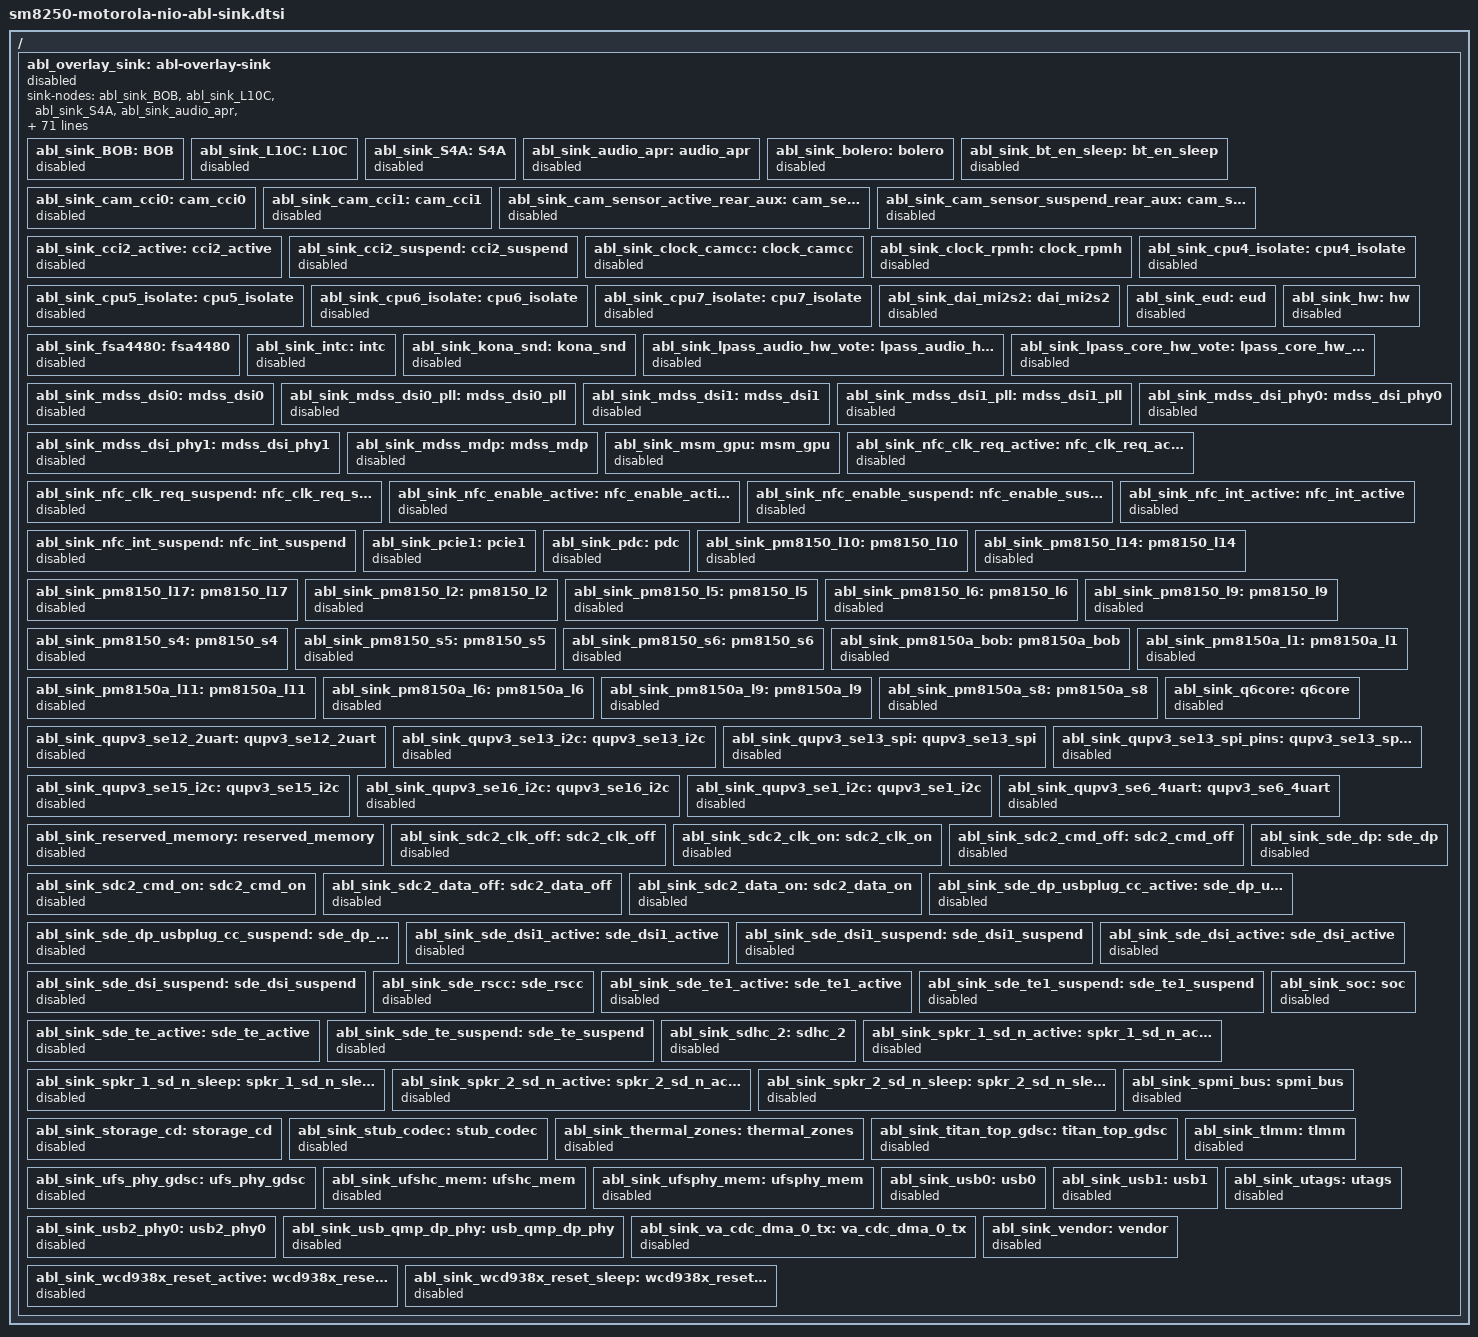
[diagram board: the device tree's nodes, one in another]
// SPDX-License-Identifier: BSD-3-Clause
/* Generated by tools/gen_abl_overlay_sink.py from dtbo sha256 52f8313a3153f082198788da3f1743398a164f1865f6db5d3dace15b3edebf47.
 * Fastboot-boot only: absorbs the stock ABL dtbo overlay. Do not edit. */

/ {
	abl_overlay_sink: abl-overlay-sink {
		status = "disabled";
		/* References make dtc emit a phandle for every sink node. */
		sink-nodes = <&abl_sink_BOB &abl_sink_L10C &abl_sink_S4A &abl_sink_audio_apr &abl_sink_bolero &abl_sink_bt_en_sleep &abl_sink_cam_cci0 &abl_sink_cam_cci1 &abl_sink_cam_sensor_active_rear_aux &abl_sink_cam_sensor_suspend_rear_aux &abl_sink_cci2_active &abl_sink_cci2_suspend &abl_sink_clock_camcc &abl_sink_clock_rpmh &abl_sink_cpu4_isolate &abl_sink_cpu5_isolate &abl_sink_cpu6_isolate &abl_sink_cpu7_isolate &abl_sink_dai_mi2s2 &abl_sink_eud &abl_sink_fsa4480 &abl_sink_hw &abl_sink_intc &abl_sink_kona_snd &abl_sink_lpass_audio_hw_vote &abl_sink_lpass_core_hw_vote &abl_sink_mdss_dsi0 &abl_sink_mdss_dsi0_pll &abl_sink_mdss_dsi1 &abl_sink_mdss_dsi1_pll &abl_sink_mdss_dsi_phy0 &abl_sink_mdss_dsi_phy1 &abl_sink_mdss_mdp &abl_sink_msm_gpu &abl_sink_nfc_clk_req_active &abl_sink_nfc_clk_req_suspend &abl_sink_nfc_enable_active &abl_sink_nfc_enable_suspend &abl_sink_nfc_int_active &abl_sink_nfc_int_suspend &abl_sink_pcie1 &abl_sink_pdc &abl_sink_pm8150_l10 &abl_sink_pm8150_l14 &abl_sink_pm8150_l17 &abl_sink_pm8150_l2 &abl_sink_pm8150_l5 &abl_sink_pm8150_l6 &abl_sink_pm8150_l9 &abl_sink_pm8150_s4 &abl_sink_pm8150_s5 &abl_sink_pm8150_s6 &abl_sink_pm8150a_bob &abl_sink_pm8150a_l1 &abl_sink_pm8150a_l11 &abl_sink_pm8150a_l6 &abl_sink_pm8150a_l9 &abl_sink_pm8150a_s8 &abl_sink_q6core &abl_sink_qupv3_se12_2uart &abl_sink_qupv3_se13_i2c &abl_sink_qupv3_se13_spi &abl_sink_qupv3_se13_spi_pins &abl_sink_qupv3_se15_i2c &abl_sink_qupv3_se16_i2c &abl_sink_qupv3_se1_i2c &abl_sink_qupv3_se6_4uart &abl_sink_reserved_memory &abl_sink_sdc2_clk_off &abl_sink_sdc2_clk_on &abl_sink_sdc2_cmd_off &abl_sink_sdc2_cmd_on &abl_sink_sdc2_data_off &abl_sink_sdc2_data_on &abl_sink_sde_dp &abl_sink_sde_dp_usbplug_cc_active &abl_sink_sde_dp_usbplug_cc_suspend &abl_sink_sde_dsi1_active &abl_sink_sde_dsi1_suspend &abl_sink_sde_dsi_active &abl_sink_sde_dsi_suspend &abl_sink_sde_rscc &abl_sink_sde_te1_active &abl_sink_sde_te1_suspend &abl_sink_sde_te_active &abl_sink_sde_te_suspend &abl_sink_sdhc_2 &abl_sink_soc &abl_sink_spkr_1_sd_n_active &abl_sink_spkr_1_sd_n_sleep &abl_sink_spkr_2_sd_n_active &abl_sink_spkr_2_sd_n_sleep &abl_sink_spmi_bus &abl_sink_storage_cd &abl_sink_stub_codec &abl_sink_thermal_zones &abl_sink_titan_top_gdsc &abl_sink_tlmm &abl_sink_ufs_phy_gdsc &abl_sink_ufshc_mem &abl_sink_ufsphy_mem &abl_sink_usb0 &abl_sink_usb1 &abl_sink_usb2_phy0 &abl_sink_usb_qmp_dp_phy &abl_sink_utags &abl_sink_va_cdc_dma_0_tx &abl_sink_vendor &abl_sink_wcd938x_reset_active &abl_sink_wcd938x_reset_sleep>;

		abl_sink_BOB: BOB {
			status = "disabled";
		};
		abl_sink_L10C: L10C {
			status = "disabled";
		};
		abl_sink_S4A: S4A {
			status = "disabled";
		};
		abl_sink_audio_apr: audio_apr {
			status = "disabled";
		};
		abl_sink_bolero: bolero {
			status = "disabled";
		};
		abl_sink_bt_en_sleep: bt_en_sleep {
			status = "disabled";
		};
		abl_sink_cam_cci0: cam_cci0 {
			status = "disabled";
		};
		abl_sink_cam_cci1: cam_cci1 {
			status = "disabled";
		};
		abl_sink_cam_sensor_active_rear_aux: cam_sensor_active_rear_aux {
			status = "disabled";
		};
		abl_sink_cam_sensor_suspend_rear_aux: cam_sensor_suspend_rear_aux {
			status = "disabled";
		};
		abl_sink_cci2_active: cci2_active {
			status = "disabled";
		};
		abl_sink_cci2_suspend: cci2_suspend {
			status = "disabled";
		};
		abl_sink_clock_camcc: clock_camcc {
			status = "disabled";
		};
		abl_sink_clock_rpmh: clock_rpmh {
			status = "disabled";
		};
		abl_sink_cpu4_isolate: cpu4_isolate {
			status = "disabled";
		};
		abl_sink_cpu5_isolate: cpu5_isolate {
			status = "disabled";
		};
		abl_sink_cpu6_isolate: cpu6_isolate {
			status = "disabled";
		};
		abl_sink_cpu7_isolate: cpu7_isolate {
			status = "disabled";
		};
		abl_sink_dai_mi2s2: dai_mi2s2 {
			status = "disabled";
		};
		abl_sink_eud: eud {
			status = "disabled";
		};
		abl_sink_fsa4480: fsa4480 {
			status = "disabled";
		};
		abl_sink_hw: hw {
			status = "disabled";
		};
		abl_sink_intc: intc {
			status = "disabled";
		};
		abl_sink_kona_snd: kona_snd {
			status = "disabled";
		};
		abl_sink_lpass_audio_hw_vote: lpass_audio_hw_vote {
			status = "disabled";
		};
		abl_sink_lpass_core_hw_vote: lpass_core_hw_vote {
			status = "disabled";
		};
		abl_sink_mdss_dsi0: mdss_dsi0 {
			status = "disabled";
		};
		abl_sink_mdss_dsi0_pll: mdss_dsi0_pll {
			status = "disabled";
		};
		abl_sink_mdss_dsi1: mdss_dsi1 {
			status = "disabled";
		};
		abl_sink_mdss_dsi1_pll: mdss_dsi1_pll {
			status = "disabled";
		};
		abl_sink_mdss_dsi_phy0: mdss_dsi_phy0 {
			status = "disabled";
		};
		abl_sink_mdss_dsi_phy1: mdss_dsi_phy1 {
			status = "disabled";
		};
		abl_sink_mdss_mdp: mdss_mdp {
			status = "disabled";
		};
		abl_sink_msm_gpu: msm_gpu {
			status = "disabled";
		};
		abl_sink_nfc_clk_req_active: nfc_clk_req_active {
			status = "disabled";
		};
		abl_sink_nfc_clk_req_suspend: nfc_clk_req_suspend {
			status = "disabled";
		};
		abl_sink_nfc_enable_active: nfc_enable_active {
			status = "disabled";
		};
		abl_sink_nfc_enable_suspend: nfc_enable_suspend {
			status = "disabled";
		};
		abl_sink_nfc_int_active: nfc_int_active {
			status = "disabled";
		};
		abl_sink_nfc_int_suspend: nfc_int_suspend {
			status = "disabled";
		};
		abl_sink_pcie1: pcie1 {
			status = "disabled";
		};
		abl_sink_pdc: pdc {
			status = "disabled";
		};
		abl_sink_pm8150_l10: pm8150_l10 {
			status = "disabled";
		};
		abl_sink_pm8150_l14: pm8150_l14 {
			status = "disabled";
		};
		abl_sink_pm8150_l17: pm8150_l17 {
			status = "disabled";
		};
		abl_sink_pm8150_l2: pm8150_l2 {
			status = "disabled";
		};
		abl_sink_pm8150_l5: pm8150_l5 {
			status = "disabled";
		};
		abl_sink_pm8150_l6: pm8150_l6 {
			status = "disabled";
		};
		abl_sink_pm8150_l9: pm8150_l9 {
			status = "disabled";
		};
		abl_sink_pm8150_s4: pm8150_s4 {
			status = "disabled";
		};
		abl_sink_pm8150_s5: pm8150_s5 {
			status = "disabled";
		};
		abl_sink_pm8150_s6: pm8150_s6 {
			status = "disabled";
		};
		abl_sink_pm8150a_bob: pm8150a_bob {
			status = "disabled";
		};
		abl_sink_pm8150a_l1: pm8150a_l1 {
			status = "disabled";
		};
		abl_sink_pm8150a_l11: pm8150a_l11 {
			status = "disabled";
		};
		abl_sink_pm8150a_l6: pm8150a_l6 {
			status = "disabled";
		};
		abl_sink_pm8150a_l9: pm8150a_l9 {
			status = "disabled";
		};
		abl_sink_pm8150a_s8: pm8150a_s8 {
			status = "disabled";
		};
		abl_sink_q6core: q6core {
			status = "disabled";
		};
		abl_sink_qupv3_se12_2uart: qupv3_se12_2uart {
			status = "disabled";
		};
		abl_sink_qupv3_se13_i2c: qupv3_se13_i2c {
			status = "disabled";
		};
		abl_sink_qupv3_se13_spi: qupv3_se13_spi {
			status = "disabled";
		};
		abl_sink_qupv3_se13_spi_pins: qupv3_se13_spi_pins {
			status = "disabled";
		};
		abl_sink_qupv3_se15_i2c: qupv3_se15_i2c {
			status = "disabled";
		};
		abl_sink_qupv3_se16_i2c: qupv3_se16_i2c {
			status = "disabled";
		};
		abl_sink_qupv3_se1_i2c: qupv3_se1_i2c {
			status = "disabled";
		};
		abl_sink_qupv3_se6_4uart: qupv3_se6_4uart {
			status = "disabled";
		};
		abl_sink_reserved_memory: reserved_memory {
			status = "disabled";
		};
		abl_sink_sdc2_clk_off: sdc2_clk_off {
			status = "disabled";
		};
		abl_sink_sdc2_clk_on: sdc2_clk_on {
			status = "disabled";
		};
		abl_sink_sdc2_cmd_off: sdc2_cmd_off {
			status = "disabled";
		};
		abl_sink_sdc2_cmd_on: sdc2_cmd_on {
			status = "disabled";
		};
		abl_sink_sdc2_data_off: sdc2_data_off {
			status = "disabled";
		};
		abl_sink_sdc2_data_on: sdc2_data_on {
			status = "disabled";
		};
		abl_sink_sde_dp: sde_dp {
			status = "disabled";
		};
		abl_sink_sde_dp_usbplug_cc_active: sde_dp_usbplug_cc_active {
			status = "disabled";
		};
		abl_sink_sde_dp_usbplug_cc_suspend: sde_dp_usbplug_cc_suspend {
			status = "disabled";
		};
		abl_sink_sde_dsi1_active: sde_dsi1_active {
			status = "disabled";
		};
		abl_sink_sde_dsi1_suspend: sde_dsi1_suspend {
			status = "disabled";
		};
		abl_sink_sde_dsi_active: sde_dsi_active {
			status = "disabled";
		};
		abl_sink_sde_dsi_suspend: sde_dsi_suspend {
			status = "disabled";
		};
		abl_sink_sde_rscc: sde_rscc {
			status = "disabled";
		};
		abl_sink_sde_te1_active: sde_te1_active {
			status = "disabled";
		};
		abl_sink_sde_te1_suspend: sde_te1_suspend {
			status = "disabled";
		};
		abl_sink_sde_te_active: sde_te_active {
			status = "disabled";
		};
		abl_sink_sde_te_suspend: sde_te_suspend {
			status = "disabled";
		};
		abl_sink_sdhc_2: sdhc_2 {
			status = "disabled";
		};
		abl_sink_soc: soc {
			status = "disabled";
		};
		abl_sink_spkr_1_sd_n_active: spkr_1_sd_n_active {
			status = "disabled";
		};
		abl_sink_spkr_1_sd_n_sleep: spkr_1_sd_n_sleep {
			status = "disabled";
		};
		abl_sink_spkr_2_sd_n_active: spkr_2_sd_n_active {
			status = "disabled";
		};
		abl_sink_spkr_2_sd_n_sleep: spkr_2_sd_n_sleep {
			status = "disabled";
		};
		abl_sink_spmi_bus: spmi_bus {
			status = "disabled";
		};
		abl_sink_storage_cd: storage_cd {
			status = "disabled";
		};
		abl_sink_stub_codec: stub_codec {
			status = "disabled";
		};
		abl_sink_thermal_zones: thermal_zones {
			status = "disabled";
		};
		abl_sink_titan_top_gdsc: titan_top_gdsc {
			status = "disabled";
		};
		abl_sink_tlmm: tlmm {
			status = "disabled";
		};
		abl_sink_ufs_phy_gdsc: ufs_phy_gdsc {
			status = "disabled";
		};
		abl_sink_ufshc_mem: ufshc_mem {
			status = "disabled";
		};
		abl_sink_ufsphy_mem: ufsphy_mem {
			status = "disabled";
		};
		abl_sink_usb0: usb0 {
			status = "disabled";
		};
		abl_sink_usb1: usb1 {
			status = "disabled";
		};
		abl_sink_usb2_phy0: usb2_phy0 {
			status = "disabled";
		};
		abl_sink_usb_qmp_dp_phy: usb_qmp_dp_phy {
			status = "disabled";
		};
		abl_sink_utags: utags {
			status = "disabled";
		};
		abl_sink_va_cdc_dma_0_tx: va_cdc_dma_0_tx {
			status = "disabled";
		};
		abl_sink_vendor: vendor {
			status = "disabled";
		};
		abl_sink_wcd938x_reset_active: wcd938x_reset_active {
			status = "disabled";
		};
		abl_sink_wcd938x_reset_sleep: wcd938x_reset_sleep {
			status = "disabled";
		};
	};

	__symbols__ {
		BOB = "/abl-overlay-sink/BOB";
		L10C = "/abl-overlay-sink/L10C";
		S4A = "/abl-overlay-sink/S4A";
		audio_apr = "/abl-overlay-sink/audio_apr";
		bolero = "/abl-overlay-sink/bolero";
		bt_en_sleep = "/abl-overlay-sink/bt_en_sleep";
		cam_cci0 = "/abl-overlay-sink/cam_cci0";
		cam_cci1 = "/abl-overlay-sink/cam_cci1";
		cam_sensor_active_rear_aux = "/abl-overlay-sink/cam_sensor_active_rear_aux";
		cam_sensor_suspend_rear_aux = "/abl-overlay-sink/cam_sensor_suspend_rear_aux";
		cci2_active = "/abl-overlay-sink/cci2_active";
		cci2_suspend = "/abl-overlay-sink/cci2_suspend";
		clock_camcc = "/abl-overlay-sink/clock_camcc";
		clock_rpmh = "/abl-overlay-sink/clock_rpmh";
		cpu4_isolate = "/abl-overlay-sink/cpu4_isolate";
		cpu5_isolate = "/abl-overlay-sink/cpu5_isolate";
		cpu6_isolate = "/abl-overlay-sink/cpu6_isolate";
		cpu7_isolate = "/abl-overlay-sink/cpu7_isolate";
		dai_mi2s2 = "/abl-overlay-sink/dai_mi2s2";
		eud = "/abl-overlay-sink/eud";
		fsa4480 = "/abl-overlay-sink/fsa4480";
		hw = "/abl-overlay-sink/hw";
		intc = "/abl-overlay-sink/intc";
		kona_snd = "/abl-overlay-sink/kona_snd";
		lpass_audio_hw_vote = "/abl-overlay-sink/lpass_audio_hw_vote";
		lpass_core_hw_vote = "/abl-overlay-sink/lpass_core_hw_vote";
		mdss_dsi0 = "/abl-overlay-sink/mdss_dsi0";
		mdss_dsi0_pll = "/abl-overlay-sink/mdss_dsi0_pll";
		mdss_dsi1 = "/abl-overlay-sink/mdss_dsi1";
		mdss_dsi1_pll = "/abl-overlay-sink/mdss_dsi1_pll";
		mdss_dsi_phy0 = "/abl-overlay-sink/mdss_dsi_phy0";
		mdss_dsi_phy1 = "/abl-overlay-sink/mdss_dsi_phy1";
		mdss_mdp = "/abl-overlay-sink/mdss_mdp";
		msm_gpu = "/abl-overlay-sink/msm_gpu";
		nfc_clk_req_active = "/abl-overlay-sink/nfc_clk_req_active";
		nfc_clk_req_suspend = "/abl-overlay-sink/nfc_clk_req_suspend";
		nfc_enable_active = "/abl-overlay-sink/nfc_enable_active";
		nfc_enable_suspend = "/abl-overlay-sink/nfc_enable_suspend";
		nfc_int_active = "/abl-overlay-sink/nfc_int_active";
		nfc_int_suspend = "/abl-overlay-sink/nfc_int_suspend";
		pcie1 = "/abl-overlay-sink/pcie1";
		pdc = "/abl-overlay-sink/pdc";
		pm8150_l10 = "/abl-overlay-sink/pm8150_l10";
		pm8150_l14 = "/abl-overlay-sink/pm8150_l14";
		pm8150_l17 = "/abl-overlay-sink/pm8150_l17";
		pm8150_l2 = "/abl-overlay-sink/pm8150_l2";
		pm8150_l5 = "/abl-overlay-sink/pm8150_l5";
		pm8150_l6 = "/abl-overlay-sink/pm8150_l6";
		pm8150_l9 = "/abl-overlay-sink/pm8150_l9";
		pm8150_s4 = "/abl-overlay-sink/pm8150_s4";
		pm8150_s5 = "/abl-overlay-sink/pm8150_s5";
		pm8150_s6 = "/abl-overlay-sink/pm8150_s6";
		pm8150a_bob = "/abl-overlay-sink/pm8150a_bob";
		pm8150a_l1 = "/abl-overlay-sink/pm8150a_l1";
		pm8150a_l11 = "/abl-overlay-sink/pm8150a_l11";
		pm8150a_l6 = "/abl-overlay-sink/pm8150a_l6";
		pm8150a_l9 = "/abl-overlay-sink/pm8150a_l9";
		pm8150a_s8 = "/abl-overlay-sink/pm8150a_s8";
		q6core = "/abl-overlay-sink/q6core";
		qupv3_se12_2uart = "/abl-overlay-sink/qupv3_se12_2uart";
		qupv3_se13_i2c = "/abl-overlay-sink/qupv3_se13_i2c";
		qupv3_se13_spi = "/abl-overlay-sink/qupv3_se13_spi";
		qupv3_se13_spi_pins = "/abl-overlay-sink/qupv3_se13_spi_pins";
		qupv3_se15_i2c = "/abl-overlay-sink/qupv3_se15_i2c";
		qupv3_se16_i2c = "/abl-overlay-sink/qupv3_se16_i2c";
		qupv3_se1_i2c = "/abl-overlay-sink/qupv3_se1_i2c";
		qupv3_se6_4uart = "/abl-overlay-sink/qupv3_se6_4uart";
		reserved_memory = "/abl-overlay-sink/reserved_memory";
		sdc2_clk_off = "/abl-overlay-sink/sdc2_clk_off";
		sdc2_clk_on = "/abl-overlay-sink/sdc2_clk_on";
		sdc2_cmd_off = "/abl-overlay-sink/sdc2_cmd_off";
		sdc2_cmd_on = "/abl-overlay-sink/sdc2_cmd_on";
		sdc2_data_off = "/abl-overlay-sink/sdc2_data_off";
		sdc2_data_on = "/abl-overlay-sink/sdc2_data_on";
		sde_dp = "/abl-overlay-sink/sde_dp";
		sde_dp_usbplug_cc_active = "/abl-overlay-sink/sde_dp_usbplug_cc_active";
		sde_dp_usbplug_cc_suspend = "/abl-overlay-sink/sde_dp_usbplug_cc_suspend";
		sde_dsi1_active = "/abl-overlay-sink/sde_dsi1_active";
		sde_dsi1_suspend = "/abl-overlay-sink/sde_dsi1_suspend";
		sde_dsi_active = "/abl-overlay-sink/sde_dsi_active";
		sde_dsi_suspend = "/abl-overlay-sink/sde_dsi_suspend";
		sde_rscc = "/abl-overlay-sink/sde_rscc";
		sde_te1_active = "/abl-overlay-sink/sde_te1_active";
		sde_te1_suspend = "/abl-overlay-sink/sde_te1_suspend";
		sde_te_active = "/abl-overlay-sink/sde_te_active";
		sde_te_suspend = "/abl-overlay-sink/sde_te_suspend";
		sdhc_2 = "/abl-overlay-sink/sdhc_2";
		soc = "/abl-overlay-sink/soc";
		spkr_1_sd_n_active = "/abl-overlay-sink/spkr_1_sd_n_active";
		spkr_1_sd_n_sleep = "/abl-overlay-sink/spkr_1_sd_n_sleep";
		spkr_2_sd_n_active = "/abl-overlay-sink/spkr_2_sd_n_active";
		spkr_2_sd_n_sleep = "/abl-overlay-sink/spkr_2_sd_n_sleep";
		spmi_bus = "/abl-overlay-sink/spmi_bus";
		storage_cd = "/abl-overlay-sink/storage_cd";
		stub_codec = "/abl-overlay-sink/stub_codec";
		thermal_zones = "/abl-overlay-sink/thermal_zones";
		titan_top_gdsc = "/abl-overlay-sink/titan_top_gdsc";
		tlmm = "/abl-overlay-sink/tlmm";
		ufs_phy_gdsc = "/abl-overlay-sink/ufs_phy_gdsc";
		ufshc_mem = "/abl-overlay-sink/ufshc_mem";
		ufsphy_mem = "/abl-overlay-sink/ufsphy_mem";
		usb0 = "/abl-overlay-sink/usb0";
		usb1 = "/abl-overlay-sink/usb1";
		usb2_phy0 = "/abl-overlay-sink/usb2_phy0";
		usb_qmp_dp_phy = "/abl-overlay-sink/usb_qmp_dp_phy";
		utags = "/abl-overlay-sink/utags";
		va_cdc_dma_0_tx = "/abl-overlay-sink/va_cdc_dma_0_tx";
		vendor = "/abl-overlay-sink/vendor";
		wcd938x_reset_active = "/abl-overlay-sink/wcd938x_reset_active";
		wcd938x_reset_sleep = "/abl-overlay-sink/wcd938x_reset_sleep";
	};
};
